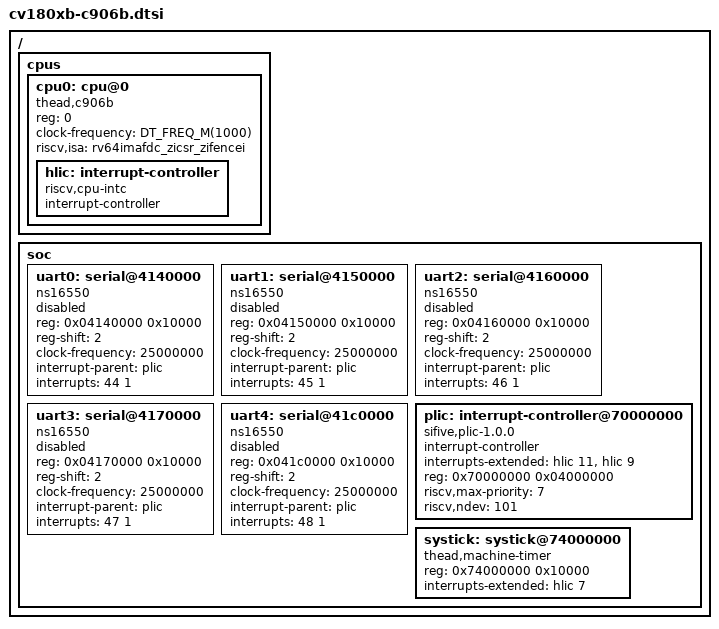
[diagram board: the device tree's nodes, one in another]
#include <freq.h>

/dts-v1/;

/ {
	cpus {
		#address-cells = <1>;
		#size-cells = <0>;
		cpu0: cpu@0 {
			compatible = "thead,c906b";
			reg = <0>;
			clock-frequency = <DT_FREQ_M(1000)>;
			riscv,isa = "rv64imafdc_zicsr_zifencei";

			hlic: interrupt-controller {
				compatible = "riscv,cpu-intc";
				#address-cells = <0>;
				#interrupt-cells = <1>;
				interrupt-controller;
			};
		};
	};

	soc {
		#address-cells = <1>;
		#size-cells = <1>;

		uart0:  serial@4140000 {
			compatible = "ns16550";
			reg = <0x04140000 0x10000>;
			reg-shift = <2>;
			clock-frequency = <25000000>;
			interrupt-parent = <&plic>;
			interrupts = <44 1>;
			status = "disabled";
		};

		uart1:  serial@4150000 {
			compatible = "ns16550";
			reg = <0x04150000 0x10000>;
			reg-shift = <2>;
			clock-frequency = <25000000>;
			interrupt-parent = <&plic>;
			interrupts = <45 1>;
			status = "disabled";
		};

		uart2:  serial@4160000 {
			compatible = "ns16550";
			reg = <0x04160000 0x10000>;
			reg-shift = <2>;
			clock-frequency = <25000000>;
			interrupt-parent = <&plic>;
			interrupts = <46 1>;
			status = "disabled";
		};

		uart3:  serial@4170000 {
			compatible = "ns16550";
			reg = <0x04170000 0x10000>;
			reg-shift = <2>;
			clock-frequency = <25000000>;
			interrupt-parent = <&plic>;
			interrupts = <47 1>;
			status = "disabled";
		};

		uart4:  serial@41c0000 {
			compatible = "ns16550";
			reg = <0x041c0000 0x10000>;
			reg-shift = <2>;
			clock-frequency = <25000000>;
			interrupt-parent = <&plic>;
			interrupts = <48 1>;
			status = "disabled";
		};

		plic: interrupt-controller@70000000 {
			compatible = "sifive,plic-1.0.0";
			#address-cells = <0>;
			#interrupt-cells = <2>;
			interrupt-controller;
			interrupts-extended = <&hlic 11 &hlic 9>;
			reg = <0x70000000 0x04000000>;
			riscv,max-priority = <7>;
			riscv,ndev = <101>;
		};

		systick: systick@74000000 {
			compatible = "thead,machine-timer";
			reg = <0x74000000 0x10000>;
			interrupts-extended = <&hlic 7>;
		};

	};
};
